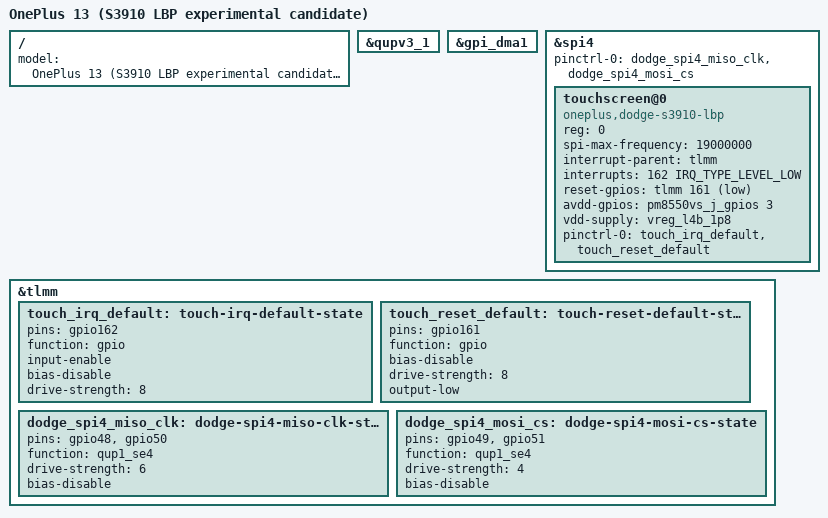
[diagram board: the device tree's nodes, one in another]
// SPDX-License-Identifier: BSD-3-Clause
/* Single-subsystem candidate. No native display or radio is enabled here. */
#include "sm8750-oneplus-dodge.dts"

/ { model = "OnePlus 13 (S3910 LBP experimental candidate)"; };

&qupv3_1 { status = "okay"; };
&gpi_dma1 { status = "okay"; };

&spi4 {
	status = "okay";
	pinctrl-0 = <&dodge_spi4_miso_clk>, <&dodge_spi4_mosi_cs>;
	touchscreen@0 {
		compatible = "oneplus,dodge-s3910-lbp";
		reg = <0>;
		spi-max-frequency = <19000000>;
		interrupt-parent = <&tlmm>;
		interrupts = <162 IRQ_TYPE_LEVEL_LOW>;
		reset-gpios = <&tlmm 161 GPIO_ACTIVE_LOW>;
		/* Vendor ignores its legacy GPIO flags and drives physical HIGH. */
		avdd-gpios = <&pm8550vs_j_gpios 3 GPIO_ACTIVE_HIGH>;
		vdd-supply = <&vreg_l4b_1p8>;
		pinctrl-names = "default";
		pinctrl-0 = <&touch_irq_default>, <&touch_reset_default>;
	};
};

&tlmm {
	touch_irq_default: touch-irq-default-state {
		pins = "gpio162";
		function = "gpio";
		input-enable;
		bias-disable;
		drive-strength = <8>;
	};
	touch_reset_default: touch-reset-default-state {
		pins = "gpio161";
		function = "gpio";
		bias-disable;
		drive-strength = <8>;
		output-low;
	};
	dodge_spi4_miso_clk: dodge-spi4-miso-clk-state {
		pins = "gpio48", "gpio50";
		function = "qup1_se4";
		drive-strength = <6>;
		bias-disable;
	};
	dodge_spi4_mosi_cs: dodge-spi4-mosi-cs-state {
		pins = "gpio49", "gpio51";
		function = "qup1_se4";
		drive-strength = <4>;
		bias-disable;
	};
};
